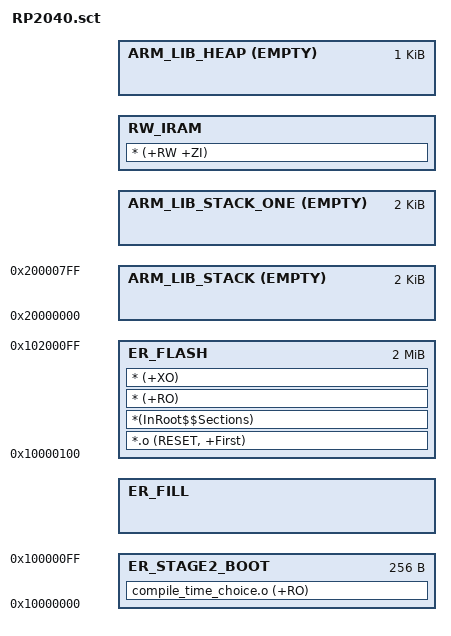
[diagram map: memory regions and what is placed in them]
; *************************************************************
; *** Scatter-Loading Description File generated by uVision ***
; *************************************************************

LR_STAGE2_BOOT 0x10000000 0x100 {
    ER_STAGE2_BOOT +0 0x100 {
        compile_time_choice.o (+RO)
    }
    ER_FILL ImageLimit(ER_STAGE2_BOOT) FILL 0xDEADBEEF 0x100 - ImageLength(ER_STAGE2_BOOT) {
    }
}

LR_IROM1 0x10000100 0x001FFF00  {    ; load region size_region

    ER_FLASH +0 0x00200000  {  ; load address = execution address
        *.o (RESET, +First)
        *(InRoot$$Sections)
        * (+RO)
        * (+XO)
    }
    
    ARM_LIB_STACK 0x20000000 ALIGN 8  EMPTY 0x00000800 {
    }
    
    ARM_LIB_STACK_ONE +0 ALIGN 8  EMPTY 0x00000800 {
    }
    
    RW_IRAM +0  {  ; RW data
        * (+RW +ZI)
    }
    
    ARM_LIB_HEAP  +0 ALIGN 8 EMPTY 0x00000400  {
    }
}

